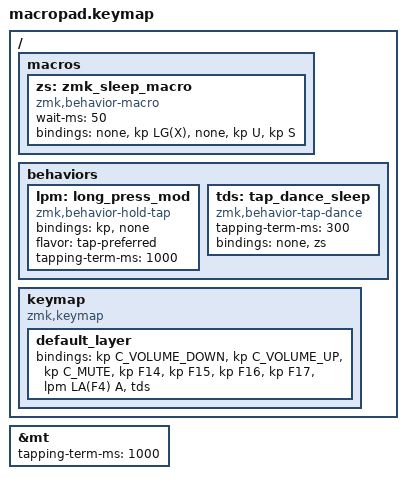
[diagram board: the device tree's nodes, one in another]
#include <behaviors.dtsi>
#include <dt-bindings/zmk/keys.h>

&mt {
    tapping-term-ms = <1000>;
};

/ {
    macros {
        zs: zmk_sleep_macro {
            compatible = "zmk,behavior-macro";
            #binding-cells = <0>;
            wait-ms = <50>;
            bindings = <&none &kp LG(X) &none &kp U &kp S>;
        };
    };

    behaviors{
        lpm: long_press_mod {
            compatible = "zmk,behavior-hold-tap";
            #binding-cells = <2>;
            bindings = <&kp>, <&none>;
            flavor = "tap-preferred";
            tapping-term-ms = <1000>;   
        };

        tds: tap_dance_sleep {
            compatible = "zmk,behavior-tap-dance";
            #binding-cells = <0>;
            tapping-term-ms = <300>;
            bindings = <&none>, <&zs>;
        };

    };

    keymap {
            compatible = "zmk,keymap";

            default_layer {
                bindings = <
                    &kp C_VOLUME_DOWN
                    &kp C_VOLUME_UP
                    &kp C_MUTE
                    &kp F14
                    &kp F15
                    &kp F16
                    &kp F17
                    &lpm LA(F4) A
                    &tds 
                    >;
            };
        };
};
